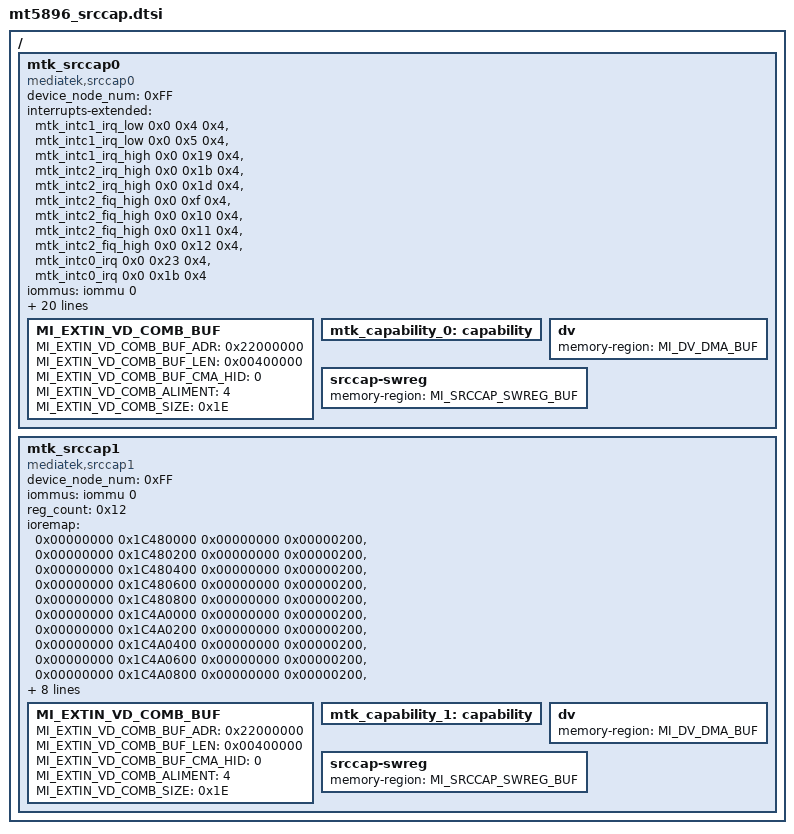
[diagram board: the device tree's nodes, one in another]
// SPDX-License-Identifier: (GPL-2.0 OR BSD-3-Clause)
/*
 * Copyright (c) 2020 MediaTek Inc.
 */

/ {
	mtk_srccap0: mtk_srccap0 {
		compatible = "mediatek,srccap0";
		device_node_num = <0xFF>; /* 0xFF for unspecified node num */
		interrupts-extended = <&mtk_intc1_irq_low 0x0 0x4 0x4>,   /*phy*/
				      <&mtk_intc1_irq_low 0x0 0x5 0x4>,   /*mac*/
				      <&mtk_intc1_irq_high 0x0 0x19 0x4>, /*pkt que*/
				      <&mtk_intc2_irq_high 0x0 0x1b 0x4>, /*pm sqh all wk pm27*/
				      <&mtk_intc2_irq_high 0x0 0x1d 0x4>, /*pm scdc 29*/
				      <&mtk_intc2_fiq_high 0x0 0xf 0x4>,  /*pm clk det fiq0*/
				      <&mtk_intc2_fiq_high 0x0 0x10 0x4>, /*pm clk det fiq1*/
				      <&mtk_intc2_fiq_high 0x0 0x11 0x4>, /*pm clk det fiq2*/
				      <&mtk_intc2_fiq_high 0x0 0x12 0x4>, /*pm clk det fiq3*/
				      <&mtk_intc0_irq 0x0 0x23 0x4>,	  /*xc_int*/
				      <&mtk_intc0_irq 0x0 0x1b 0x4>;      /*vbi*/
		iommus = <&iommu 0>;

		reg_count = <0x12>;
		ioremap = <0x00000000 0x1C480000 0x00000000 0x00000200>, /* adc_atop(2400H)*/
				<0x00000000 0x1C480200 0x00000000 0x00000200>, /* adc_dtop(2401H)*/
				<0x00000000 0x1C480400 0x00000000 0x00000200>, /* adc_dtopb(2402H)*/
				<0x00000000 0x1C480600 0x00000000 0x00000200>, /* adc_atopb(2403H)*/
				<0x00000000 0x1C480800 0x00000000 0x00000200>, /* adc_pllm(2404H)*/
				<0x00000000 0x1C4A0000 0x00000000 0x00000200>, /* afec(2500H) */
				<0x00000000 0x1C4A0200 0x00000000 0x00000200>, /* vbi(2501H) */
				<0x00000000 0x1C4A0400 0x00000000 0x00000200>, /* scm(2502H) */
				<0x00000000 0x1C4A0600 0x00000000 0x00000200>, /* comb(2503H) */
				<0x00000000 0x1C4A0800 0x00000000 0x00000200>, /* comb1(2504H) */
				<0x00000000 0x1C4A0A00 0x00000000 0x00000200>, /* comb2(2505H) */
				<0x00000000 0x1C4A0C00 0x00000000 0x00000200>, /* comb3(2506H) */
				<0x00000000 0x1C4A0E00 0x00000000 0x00000200>, /* comb4(2507H) */
				<0x00000000 0x1C4A1000 0x00000000 0x00000200>, /* comb5(2508H) */
				<0x00000000 0x1CC02000 0x00000000 0x00000200>, /* vdmcu51(6010H) */
				<0x00000000 0x1CC03600 0x00000000 0x00000100>, /* 601BH */
				<0x00000000 0x1CC03800 0x00000000 0x00000200>, /* 691CH */
				<0x00000000 0x1C601E00 0x00000000 0x00000100>; /* 300FH */
		MI_EXTIN_VD_COMB_BUF {
			MI_EXTIN_VD_COMB_BUF_ADR = <0x22000000>;
			MI_EXTIN_VD_COMB_BUF_LEN = <0x00400000>;
			MI_EXTIN_VD_COMB_BUF_CMA_HID = <0>;
			MI_EXTIN_VD_COMB_ALIMENT = <4>;
			MI_EXTIN_VD_COMB_SIZE = <0x1E>;
		};
		mtk_capability_0: capability {
		};
		dv {
			memory-region = <&MI_DV_DMA_BUF>;
		};
		srccap-swreg {
			memory-region = <&MI_SRCCAP_SWREG_BUF>;
		};
	};

	mtk_srccap1: mtk_srccap1 {
		compatible = "mediatek,srccap1";
		device_node_num = <0xFF>; /* 0xFF for unspecified node num */
		iommus = <&iommu 0>;
		reg_count = <0x12>;
		ioremap = <0x00000000 0x1C480000 0x00000000 0x00000200>, /* adc_atop(2400H)*/
				<0x00000000 0x1C480200 0x00000000 0x00000200>, /* adc_dtop(2401H)*/
				<0x00000000 0x1C480400 0x00000000 0x00000200>, /* adc_dtopb(2402H)*/
				<0x00000000 0x1C480600 0x00000000 0x00000200>, /* adc_atopb(2403H)*/
				<0x00000000 0x1C480800 0x00000000 0x00000200>, /* adc_pllm(2404H)*/
				<0x00000000 0x1C4A0000 0x00000000 0x00000200>, /* afec(2500H) */
				<0x00000000 0x1C4A0200 0x00000000 0x00000200>, /* vbi(2501H) */
				<0x00000000 0x1C4A0400 0x00000000 0x00000200>, /* scm(2502H) */
				<0x00000000 0x1C4A0600 0x00000000 0x00000200>, /* comb(2503H) */
				<0x00000000 0x1C4A0800 0x00000000 0x00000200>, /* comb1(2504H) */
				<0x00000000 0x1C4A0A00 0x00000000 0x00000200>, /* comb2(2505H) */
				<0x00000000 0x1C4A0C00 0x00000000 0x00000200>, /* comb3(2506H) */
				<0x00000000 0x1C4A0E00 0x00000000 0x00000200>, /* comb4(2507H) */
				<0x00000000 0x1C4A1000 0x00000000 0x00000200>, /* comb5(2508H) */
				<0x00000000 0x1CC02000 0x00000000 0x00000200>, /* vdmcu51(6010H) */
				<0x00000000 0x1CC03600 0x00000000 0x00000100>, /* 601BH */
				<0x00000000 0x1CC03800 0x00000000 0x00000200>, /* 691CH */
				<0x00000000 0x1C601E00 0x00000000 0x00000100>; /* 300FH */
		MI_EXTIN_VD_COMB_BUF {
			MI_EXTIN_VD_COMB_BUF_ADR = <0x22000000>;
			MI_EXTIN_VD_COMB_BUF_LEN = <0x00400000>;
			MI_EXTIN_VD_COMB_BUF_CMA_HID = <0>;
			MI_EXTIN_VD_COMB_ALIMENT = <4>;
			MI_EXTIN_VD_COMB_SIZE = <0x1E>;
		};
		mtk_capability_1: capability {
		};
		dv {
			memory-region = <&MI_DV_DMA_BUF>;
		};
		srccap-swreg {
			memory-region = <&MI_SRCCAP_SWREG_BUF>;
		};
	};
};
